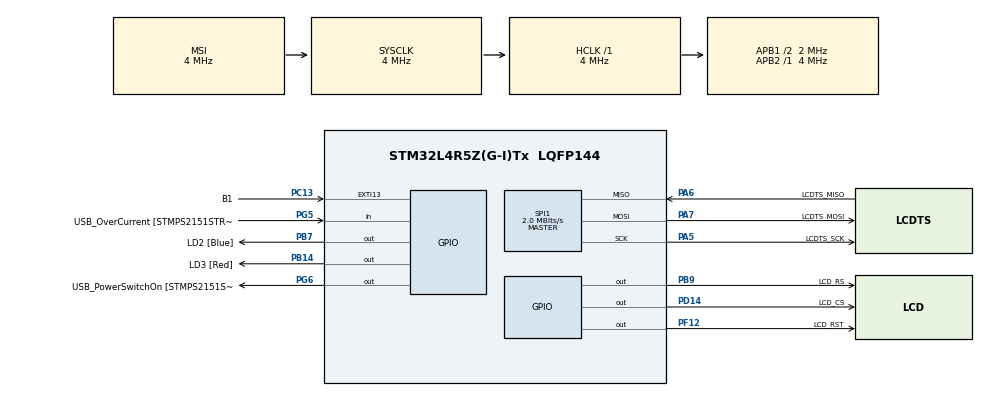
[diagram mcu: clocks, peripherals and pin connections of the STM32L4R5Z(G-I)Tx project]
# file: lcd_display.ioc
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Dma.Request0=SPI1_RX
Dma.Request1=SPI1_TX
Dma.SPI1_RX.0.Direction=DMA_PERIPH_TO_MEMORY
Dma.SPI1_RX.0.EventEnable=DISABLE
Dma.SPI1_RX.0.Instance=DMA1_Channel1
Dma.SPI1_RX.0.MemDataAlignment=DMA_MDATAALIGN_BYTE
Dma.SPI1_RX.0.MemInc=DMA_MINC_ENABLE
Dma.SPI1_RX.0.Mode=DMA_NORMAL
Dma.SPI1_RX.0.PeriphDataAlignment=DMA_PDATAALIGN_HALFWORD
Dma.SPI1_RX.0.PeriphInc=DMA_PINC_DISABLE
Dma.SPI1_RX.0.Polarity=HAL_DMAMUX_REQUEST_GEN_RISING
Dma.SPI1_RX.0.Priority=DMA_PRIORITY_LOW
Dma.SPI1_RX.0.RequestNumber=1
Dma.SPI1_RX.0.SignalID=NONE
Dma.SPI1_RX.0.SyncEnable=DISABLE
Dma.SPI1_RX.0.SyncPolarity=HAL_DMAMUX_SYNC_NO_EVENT
Dma.SPI1_RX.0.SyncRequestNumber=1
Dma.SPI1_RX.0.SyncSignalID=NONE
Dma.SPI1_TX.1.Direction=DMA_MEMORY_TO_PERIPH
Dma.SPI1_TX.1.EventEnable=DISABLE
Dma.SPI1_TX.1.Instance=DMA1_Channel2
Dma.SPI1_TX.1.MemDataAlignment=DMA_MDATAALIGN_BYTE
Dma.SPI1_TX.1.MemInc=DMA_MINC_ENABLE
Dma.SPI1_TX.1.Mode=DMA_NORMAL
Dma.SPI1_TX.1.PeriphDataAlignment=DMA_PDATAALIGN_BYTE
Dma.SPI1_TX.1.PeriphInc=DMA_PINC_DISABLE
Dma.SPI1_TX.1.Polarity=HAL_DMAMUX_REQUEST_GEN_RISING
Dma.SPI1_TX.1.Priority=DMA_PRIORITY_LOW
Dma.SPI1_TX.1.RequestNumber=1
Dma.SPI1_TX.1.SignalID=NONE
Dma.SPI1_TX.1.SyncEnable=DISABLE
Dma.SPI1_TX.1.SyncPolarity=HAL_DMAMUX_SYNC_NO_EVENT
Dma.SPI1_TX.1.SyncRequestNumber=1
Dma.SPI1_TX.1.SyncSignalID=NONE
Mcu.Family=STM32L4
Mcu.Name=STM32L4R5Z(G-I)Tx
Mcu.Package=LQFP144
NVIC.DMA1_Channel1_IRQn=true\:0\:0\:false\:false\:true\:false\:true\:true
NVIC.DMA1_Channel2_IRQn=true\:0\:0\:false\:false\:true\:false\:true\:true
NVIC.PriorityGroup=NVIC_PRIORITYGROUP_4
NVIC.SPI1_IRQn=true\:0\:0\:false\:false\:true\:true\:true\:true
PA10.GPIO_Label=USB_ID
PA10.Signal=USB_OTG_FS_ID
PA11.GPIO_Label=USB_DM
PA11.Signal=USB_OTG_FS_DM
PA12.GPIO_Label=USB_DP
PA12.Signal=USB_OTG_FS_DP
PA13\ (JTMS/SWDIO).GPIO_Label=TMS
PA13\ (JTMS/SWDIO).Mode=Trace_Asynchronous_SW
PA13\ (JTMS/SWDIO).Signal=SYS_JTMS-SWDIO
PA14\ (JTCK/SWCLK).GPIO_Label=TCK
PA14\ (JTCK/SWCLK).Mode=Trace_Asynchronous_SW
PA14\ (JTCK/SWCLK).Signal=SYS_JTCK-SWCLK
PA5.GPIO_Label=LCDTS_SCK
PA5.Mode=Full_Duplex_Master
PA5.Signal=SPI1_SCK
PA6.GPIO_Label=LCDTS_MISO
PA6.Mode=Full_Duplex_Master
PA6.Signal=SPI1_MISO
PA7.GPIO_Label=LCDTS_MOSI
PA7.Mode=Full_Duplex_Master
PA7.Signal=SPI1_MOSI
PA8.GPIO_Label=USB_SOF [TP1]
PA8.Signal=USB_OTG_FS_SOF
PA9.GPIO_Label=USB_VBUS
PA9.Signal=USB_OTG_FS_VBUS
PB14.GPIO_Label=LD3 [Red]
PB14.PinState=GPIO_PIN_RESET
PB14.Signal=GPIO_Output
PB3\ (JTDO/TRACESWO).GPIO_Label=SWO
PB3\ (JTDO/TRACESWO).Mode=Trace_Asynchronous_SW
PB3\ (JTDO/TRACESWO).Signal=SYS_JTDO-SWO
PB7.GPIO_Label=LD2 [Blue]
PB7.Signal=GPIO_Output
PB9.GPIO_Label=LCD_RS
PB9.GPIO_Speed=GPIO_SPEED_FREQ_VERY_HIGH
PB9.Signal=GPIO_Output
PC13.GPIO_Label=B1
PC13.Signal=GPXTI13
PC14-OSC32_IN\ (PC14).Mode=LSE-External-Oscillator
PC14-OSC32_IN\ (PC14).Signal=RCC_OSC32_IN
PC15-OSC32_OUT\ (PC15).Mode=LSE-External-Oscillator
PC15-OSC32_OUT\ (PC15).Signal=RCC_OSC32_OUT
PD14.GPIO_Label=LCD_CS
PD14.GPIO_Speed=GPIO_SPEED_FREQ_VERY_HIGH
PD14.PinState=GPIO_PIN_SET
PD14.Signal=GPIO_Output
PD8.GPIO_Label=STLK_RX [STM32F103CBT6_PA3]
PD8.Signal=USART3_TX
PD9.GPIO_Label=STLK_TX [STM32F103CBT6_PA2]
PD9.Signal=USART3_RX
PF12.GPIO_Label=LCD_RST
PF12.GPIO_Speed=GPIO_SPEED_FREQ_LOW
PF12.PinState=GPIO_PIN_SET
PF12.Signal=GPIO_Output
PG5.GPIO_Label=USB_OverCurrent [STMPS2151STR_FAULT]
PG5.Signal=GPIO_Input
PG6.GPIO_Label=USB_PowerSwitchOn [STMPS2151STR_En]
PG6.Signal=GPIO_Output
PG7.GPIO_Label=STLINK_TX
PG7.Signal=LPUART1_TX
PG8.GPIO_Label=STLINK_RX
PG8.Signal=LPUART1_RX
PH0-OSC_IN\ (PH0).Mode=HSE-External-Clock-Source
PH0-OSC_IN\ (PH0).Signal=RCC_OSC_IN
PH1-OSC_OUT\ (PH1).Signal=RCC_OSC_OUT
ProjectManager.HeapSize=0x200
ProjectManager.StackSize=0x400
ProjectManager.TargetToolchain=STM32CubeIDE
RCC.48MHZClocksFreq_Value=24000000
RCC.ADCFreq_Value=16000000
RCC.AHBFreq_Value=4000000
RCC.APB1CLKDivider=RCC_HCLK_DIV2
RCC.APB1Freq_Value=2000000
RCC.APB1TimFreq_Value=4000000
RCC.APB2Freq_Value=4000000
RCC.APB2TimFreq_Value=4000000
RCC.CortexFreq_Value=4000000
RCC.HCLKFreq_Value=4000000
RCC.HSI48_VALUE=48000000
RCC.HSI_VALUE=16000000
RCC.MSI_VALUE=4000000
RCC.PLLMUL=RCC_PLL_MUL9
RCC.PRESCALERUSB=RCC_USBCLKSOURCE_PLL_DIV1_5
RCC.SYSCLKFreq_VALUE=4000000
RCC.SYSCLKSourceVirtual=RCC_SYSCLKSOURCE_PLLCLK
RCC.USBFreq_Value=16000000
RCC.VCOOutputFreq_Value=32000000
SPI1.BaudRatePrescaler=SPI_BAUDRATEPRESCALER_2
SPI1.CalculateBaudRate=2.0 MBits/s
SPI1.DataSize=SPI_DATASIZE_8BIT
SPI1.Direction=SPI_DIRECTION_2LINES
SPI1.Mode=SPI_MODE_MASTER
SPI1.VirtualType=VM_MASTER
board=NUCLEO-L4R5ZI

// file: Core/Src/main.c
/* USER CODE BEGIN Header */
/**
  ******************************************************************************
  * @file           : main.c
  * @brief          : Main program body
  ******************************************************************************
  * @attention
  *
  * Copyright (c) 2025 STMicroelectronics.
  * All rights reserved.
  *
  * This software is licensed under terms that can be found in the LICENSE file
  * in the root directory of this software component.
  * If no LICENSE file comes with this software, it is provided AS-IS.
  *
  ******************************************************************************
  */
/* USER CODE END Header */
#include "main.h"
/* USER CODE BEGIN Includes */
// include the app to run before main
/* USER CODE END Includes */

SPI_HandleTypeDef hspi1;
DMA_HandleTypeDef hdma_spi1_rx;
DMA_HandleTypeDef hdma_spi1_tx;

void SystemClock_Config(void);
static void MX_GPIO_Init(void);
static void MX_DMA_Init(void);
static void MX_SPI1_Init(void);
/* USER CODE BEGIN PFP */
extern LCD_DrvTypeDef *lcd_drv;
/* USER CODE END PFP */

int main(void)
{

  /* MCU Configuration--------------------------------------------------------*/

  /* Reset of all peripherals, Initializes the Flash interface and the Systick. */
  HAL_Init();

  /* Configure the system clock */
  SystemClock_Config();

  /* Initialize all configured peripherals */
  MX_GPIO_Init();
  MX_DMA_Init();
  MX_SPI1_Init();

  /* Infinite loop */
  /* USER CODE BEGIN WHILE */
   mainApp();
  while (1)
  {
    /* USER CODE END WHILE */

  }
}

void SystemClock_Config(void)
{
  RCC_OscInitTypeDef RCC_OscInitStruct = {0};
  RCC_ClkInitTypeDef RCC_ClkInitStruct = {0};

  /** Configure the main internal regulator output voltage
  */
  if (HAL_PWREx_ControlVoltageScaling(PWR_REGULATOR_VOLTAGE_SCALE1) != HAL_OK)
  {
    Error_Handler();
  }

  /** Initializes the RCC Oscillators according to the specified parameters
  * in the RCC_OscInitTypeDef structure.
  */
  RCC_OscInitStruct.OscillatorType = RCC_OSCILLATORTYPE_MSI;
  RCC_OscInitStruct.MSIState = RCC_MSI_ON;
  RCC_OscInitStruct.MSICalibrationValue = 0;
  RCC_OscInitStruct.MSIClockRange = RCC_MSIRANGE_6;
  RCC_OscInitStruct.PLL.PLLState = RCC_PLL_NONE;
  if (HAL_RCC_OscConfig(&RCC_OscInitStruct) != HAL_OK)
  {
    Error_Handler();
  }

  /** Initializes the CPU, AHB and APB buses clocks
  */
  RCC_ClkInitStruct.ClockType = RCC_CLOCKTYPE_HCLK|RCC_CLOCKTYPE_SYSCLK
                              |RCC_CLOCKTYPE_PCLK1|RCC_CLOCKTYPE_PCLK2;
  RCC_ClkInitStruct.SYSCLKSource = RCC_SYSCLKSOURCE_MSI;
  RCC_ClkInitStruct.AHBCLKDivider = RCC_SYSCLK_DIV1;
  RCC_ClkInitStruct.APB1CLKDivider = RCC_HCLK_DIV2;
  RCC_ClkInitStruct.APB2CLKDivider = RCC_HCLK_DIV1;

  if (HAL_RCC_ClockConfig(&RCC_ClkInitStruct, FLASH_LATENCY_0) != HAL_OK)
  {
    Error_Handler();
  }
}

static void MX_SPI1_Init(void)
{

  /* SPI1 parameter configuration*/
  hspi1.Instance = SPI1;
  hspi1.Init.Mode = SPI_MODE_MASTER;
  hspi1.Init.Direction = SPI_DIRECTION_2LINES;
  hspi1.Init.DataSize = SPI_DATASIZE_8BIT;
  hspi1.Init.CLKPolarity = SPI_POLARITY_LOW;
  hspi1.Init.CLKPhase = SPI_PHASE_1EDGE;
  hspi1.Init.NSS = SPI_NSS_SOFT;
  hspi1.Init.BaudRatePrescaler = SPI_BAUDRATEPRESCALER_2;
  hspi1.Init.FirstBit = SPI_FIRSTBIT_MSB;
  hspi1.Init.TIMode = SPI_TIMODE_DISABLE;
  hspi1.Init.CRCCalculation = SPI_CRCCALCULATION_DISABLE;
  hspi1.Init.CRCPolynomial = 7;
  hspi1.Init.CRCLength = SPI_CRC_LENGTH_DATASIZE;
  hspi1.Init.NSSPMode = SPI_NSS_PULSE_ENABLE;
  if (HAL_SPI_Init(&hspi1) != HAL_OK)
  {
    Error_Handler();
  }

}

static void MX_DMA_Init(void)
{

  /* DMA controller clock enable */
  __HAL_RCC_DMAMUX1_CLK_ENABLE();
  __HAL_RCC_DMA1_CLK_ENABLE();

  /* DMA interrupt init */
  /* DMA1_Channel1_IRQn interrupt configuration */
  HAL_NVIC_SetPriority(DMA1_Channel1_IRQn, 0, 0);
  HAL_NVIC_EnableIRQ(DMA1_Channel1_IRQn);
  /* DMA1_Channel2_IRQn interrupt configuration */
  HAL_NVIC_SetPriority(DMA1_Channel2_IRQn, 0, 0);
  HAL_NVIC_EnableIRQ(DMA1_Channel2_IRQn);
  /* DMAMUX1_OVR_IRQn interrupt configuration */
  HAL_NVIC_SetPriority(DMAMUX1_OVR_IRQn, 0, 0);
  HAL_NVIC_EnableIRQ(DMAMUX1_OVR_IRQn);

}

static void MX_GPIO_Init(void)
{
  GPIO_InitTypeDef GPIO_InitStruct = {0};

  /* GPIO Ports Clock Enable */
  __HAL_RCC_GPIOC_CLK_ENABLE();
  __HAL_RCC_GPIOH_CLK_ENABLE();
  __HAL_RCC_GPIOA_CLK_ENABLE();
  __HAL_RCC_GPIOF_CLK_ENABLE();
  __HAL_RCC_GPIOB_CLK_ENABLE();
  __HAL_RCC_GPIOD_CLK_ENABLE();
  __HAL_RCC_GPIOG_CLK_ENABLE();
  HAL_PWREx_EnableVddIO2();

  /*Configure GPIO pin Output Level */
  HAL_GPIO_WritePin(LCD_RST_GPIO_Port, LCD_RST_Pin, GPIO_PIN_SET);

  /*Configure GPIO pin Output Level */
  HAL_GPIO_WritePin(GPIOB, LD3_Pin|LD2_Pin|LCD_RS_Pin, GPIO_PIN_RESET);

  /*Configure GPIO pin Output Level */
  HAL_GPIO_WritePin(LCD_CS_GPIO_Port, LCD_CS_Pin, GPIO_PIN_SET);

  /*Configure GPIO pin Output Level */
  HAL_GPIO_WritePin(USB_PowerSwitchOn_GPIO_Port, USB_PowerSwitchOn_Pin, GPIO_PIN_RESET);

  /*Configure GPIO pin : B1_Pin */
  GPIO_InitStruct.Pin = B1_Pin;
  GPIO_InitStruct.Mode = GPIO_MODE_IT_RISING;
  GPIO_InitStruct.Pull = GPIO_NOPULL;
  HAL_GPIO_Init(B1_GPIO_Port, &GPIO_InitStruct);

  /*Configure GPIO pin : LCD_RST_Pin */
  GPIO_InitStruct.Pin = LCD_RST_Pin;
  GPIO_InitStruct.Mode = GPIO_MODE_OUTPUT_PP;
  GPIO_InitStruct.Pull = GPIO_NOPULL;
  GPIO_InitStruct.Speed = GPIO_SPEED_FREQ_LOW;
  HAL_GPIO_Init(LCD_RST_GPIO_Port, &GPIO_InitStruct);

  /*Configure GPIO pins : LD3_Pin LD2_Pin */
  GPIO_InitStruct.Pin = LD3_Pin|LD2_Pin;
  GPIO_InitStruct.Mode = GPIO_MODE_OUTPUT_PP;
  GPIO_InitStruct.Pull = GPIO_NOPULL;
  GPIO_InitStruct.Speed = GPIO_SPEED_FREQ_LOW;
  HAL_GPIO_Init(GPIOB, &GPIO_InitStruct);

  /*Configure GPIO pins : STLK_RX_Pin STLK_TX_Pin */
  GPIO_InitStruct.Pin = STLK_RX_Pin|STLK_TX_Pin;
  GPIO_InitStruct.Mode = GPIO_MODE_AF_PP;
  GPIO_InitStruct.Pull = GPIO_NOPULL;
  GPIO_InitStruct.Speed = GPIO_SPEED_FREQ_VERY_HIGH;
  GPIO_InitStruct.Alternate = GPIO_AF7_USART3;
  HAL_GPIO_Init(GPIOD, &GPIO_InitStruct);

  /*Configure GPIO pin : LCD_CS_Pin */
  GPIO_InitStruct.Pin = LCD_CS_Pin;
  GPIO_InitStruct.Mode = GPIO_MODE_OUTPUT_PP;
  GPIO_InitStruct.Pull = GPIO_NOPULL;
  GPIO_InitStruct.Speed = GPIO_SPEED_FREQ_VERY_HIGH;
  HAL_GPIO_Init(LCD_CS_GPIO_Port, &GPIO_InitStruct);

  /*Configure GPIO pin : USB_OverCurrent_Pin */
  GPIO_InitStruct.Pin = USB_OverCurrent_Pin;
  GPIO_InitStruct.Mode = GPIO_MODE_INPUT;
  GPIO_InitStruct.Pull = GPIO_NOPULL;
  HAL_GPIO_Init(USB_OverCurrent_GPIO_Port, &GPIO_InitStruct);

  /*Configure GPIO pin : USB_PowerSwitchOn_Pin */
  GPIO_InitStruct.Pin = USB_PowerSwitchOn_Pin;
  GPIO_InitStruct.Mode = GPIO_MODE_OUTPUT_PP;
  GPIO_InitStruct.Pull = GPIO_NOPULL;
  GPIO_InitStruct.Speed = GPIO_SPEED_FREQ_LOW;
  HAL_GPIO_Init(USB_PowerSwitchOn_GPIO_Port, &GPIO_InitStruct);

  /*Configure GPIO pins : STLINK_TX_Pin STLINK_RX_Pin */
  GPIO_InitStruct.Pin = STLINK_TX_Pin|STLINK_RX_Pin;
  GPIO_InitStruct.Mode = GPIO_MODE_AF_PP;
  GPIO_InitStruct.Pull = GPIO_NOPULL;
  GPIO_InitStruct.Speed = GPIO_SPEED_FREQ_VERY_HIGH;
  GPIO_InitStruct.Alternate = GPIO_AF8_LPUART1;
  HAL_GPIO_Init(GPIOG, &GPIO_InitStruct);

  /*Configure GPIO pins : USB_SOF_Pin USB_ID_Pin USB_DM_Pin USB_DP_Pin */
  GPIO_InitStruct.Pin = USB_SOF_Pin|USB_ID_Pin|USB_DM_Pin|USB_DP_Pin;
  GPIO_InitStruct.Mode = GPIO_MODE_AF_PP;
  GPIO_InitStruct.Pull = GPIO_NOPULL;
  GPIO_InitStruct.Speed = GPIO_SPEED_FREQ_VERY_HIGH;
  GPIO_InitStruct.Alternate = GPIO_AF10_OTG_FS;
  HAL_GPIO_Init(GPIOA, &GPIO_InitStruct);

  /*Configure GPIO pin : USB_VBUS_Pin */
  GPIO_InitStruct.Pin = USB_VBUS_Pin;
  GPIO_InitStruct.Mode = GPIO_MODE_INPUT;
  GPIO_InitStruct.Pull = GPIO_NOPULL;
  HAL_GPIO_Init(USB_VBUS_GPIO_Port, &GPIO_InitStruct);

  /*Configure GPIO pin : LCD_RS_Pin */
  GPIO_InitStruct.Pin = LCD_RS_Pin;
  GPIO_InitStruct.Mode = GPIO_MODE_OUTPUT_PP;
  GPIO_InitStruct.Pull = GPIO_NOPULL;
  GPIO_InitStruct.Speed = GPIO_SPEED_FREQ_VERY_HIGH;
  HAL_GPIO_Init(LCD_RS_GPIO_Port, &GPIO_InitStruct);

}

void Error_Handler(void)
{
  __disable_irq();
  while (1)
  {
  }
}
